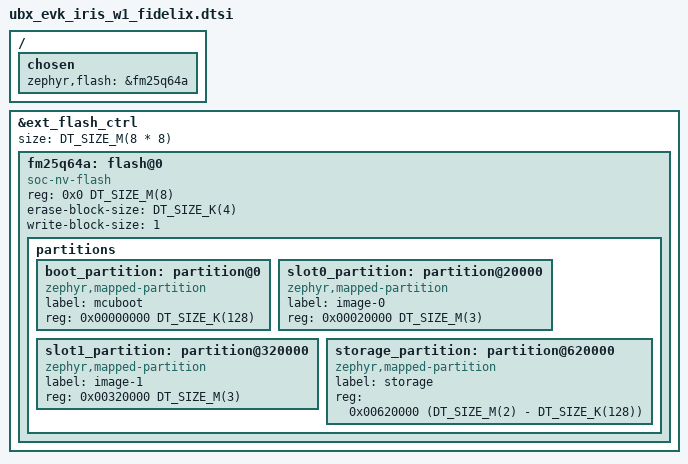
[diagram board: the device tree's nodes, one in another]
/*
 * Copyright (c) 2025 u-blox AG
 *
 * SPDX-License-Identifier: Apache-2.0
 */

/ {
	chosen {
		zephyr,flash = &fm25q64a;
	};
};

&ext_flash_ctrl {
	/* Fidelix FM25Q64A - 8MB / 64Mbit */
	size = <DT_SIZE_M(8 * 8)>;
	ranges = <0x0 0x18000000 DT_SIZE_M(8)>;

	fm25q64a: flash@0 {
		compatible = "soc-nv-flash";
		reg = <0x0 DT_SIZE_M(8)>;
		erase-block-size = <DT_SIZE_K(4)>;
		write-block-size = <1>;

		#address-cells = <1>;
		#size-cells = <1>;
		ranges;

		partitions {
			#address-cells = <1>;
			#size-cells = <1>;
			ranges;

			boot_partition: partition@0 {
				compatible = "zephyr,mapped-partition";
				label = "mcuboot";
				reg = <0x00000000 DT_SIZE_K(128)>;
			};

			slot0_partition: partition@20000 {
				compatible = "zephyr,mapped-partition";
				label = "image-0";
				reg = <0x00020000 DT_SIZE_M(3)>;
			};

			slot1_partition: partition@320000 {
				compatible = "zephyr,mapped-partition";
				label = "image-1";
				reg = <0x00320000 DT_SIZE_M(3)>;
			};

			storage_partition: partition@620000 {
				compatible = "zephyr,mapped-partition";
				label = "storage";
				reg = <0x00620000 (DT_SIZE_M(2) - DT_SIZE_K(128))>;
			};
		};
	};
};
